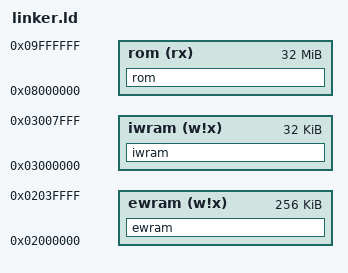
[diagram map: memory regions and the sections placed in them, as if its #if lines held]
ENTRY(__start)

gNumMusicPlayers = 0x20;
gMaxLines = 0;

MEMORY {
    ewram (w!x) : ORIGIN = 0x02000000, LENGTH = 256K
    iwram (w!x) : ORIGIN = 0x03000000, LENGTH = 32K
    rom (rx) : ORIGIN = 0x08000000, LENGTH = 32M
}

SECTIONS {
    ewram (NOLOAD) : ALIGN(4) {
        . = 0x00000010; gUnk_02000010 = .;
        . = 0x00000020; gUnk_02000020 = .;
        . = 0x00000030; gUnk_02000030 = .;
        . = 0x00000040; gUnk_02000040 = .;
        . = 0x00000050; gMessage = .;
        . = 0x00000070; gUpdateVisibleTiles = .;
        . = 0x00000080; gMenu = .;
        . = 0x00000080; gIntroState = .;
        . = 0x00000080; gChooseFileState = .;
        . = 0x00000090; gUnk_02000090 = .;
        . = 0x000000B0; gUnk_020000B0 = .;
        . = 0x000000C0; gUnk_020000C0 = .;
        . = 0x00000CC0; gBgAnimations = .;
        . = 0x00000D00; gTextGfxBuffer = .;
        . = 0x00001A00; gPaletteList = .;
        . = 0x00001A3C; gUnk_02001A3C = .;
        . = 0x00001A40; gBG3Buffer = .;
        . = 0x00002A40; gSave = .;
        . = 0x00002F00; gMapDataTopSpecial = .;
        . = 0x00006F00; gUnk_02006F00 = .;
        . = 0x0000AF00; gHUD = .;
        . = 0x0000AF34; gUnk_0200AF34 = .;
        . = 0x0000B240; gTilesForSpecialTiles = .;
        . = 0x0000B640; gUnk_0200B640 = .;
        . = 0x0000B644; gUsedPalettes = .;
        . = 0x0000B650; gMapTop = .;
        . = 0x00017654; gCurrentRoomProperties = .;
        . = 0x00017660; gSmallChests = .;
        . = 0x000176A0; gPaletteBuffer = .;
        . = 0x00017830; gUnk_02017830 = .;
        . = 0x00017AA0; gUnk_02017AA0 = .;
        . = 0x00017BA0; gUnk_02017BA0 = .;
        . = 0x00018EA0; gUnk_02018EA0 = .;
        . = 0x00018EB0; gUnk_02018EB0 = .;
        . = 0x00018EE0; gUnk_02018EE0 = .;
        . = 0x00019EE0; gMapDataBottomSpecial = .;
        . = 0x0001AEE0; gDungeonMap = .;
        . = 0x00021EE0; gSoundPlayingInfo = .;
        . = 0x00021F00; gUnk_02021F00 = .;
        . = 0x00021F20; gUnk_02021F20 = .;
        . = 0x00021F30; gBG1Buffer = .;
        . = 0x00022730; gVBlankDMA = .;
        . = 0x00022740; gFuseInfo = .;
        . = 0x00022750; gPlayerScriptExecutionContext = .;
        . = 0x00022780; gTextRender = .;
        . = 0x000227DC; gUnk_020227DC = .;
        . = 0x000227E8; gUnk_020227E8 = .;
        . = 0x000227F0; gUnk_020227F0 = .;
        . = 0x000227F8; gUnk_020227F8 = .;
        . = 0x00022800; gUnk_02022800 = .;
        . = 0x0002281D; gTextRenderUpdateDraw = .;
        . = 0x00022830; gUnk_02022830 = .;
        . = 0x00024030; gMessageChoices = .;
        . = 0x00024048; gUnk_02024048 = .;
        . = 0x00024050; gRoomMemory = .;
        . = 0x00024090; gPaletteBufferBackup = .;
        . = 0x00024490; gGFXSlots = .;
        . = 0x000246B0; gUnk_020246B0 = .;
        . = 0x00025EB0; gMapBottom = .;
        . = 0x00031EC0; gNPCData = .;
        . = 0x00032EC0; gUI = .;
        . = 0x00033280; gActiveScriptInfo = .;
        . = 0x00033290; gUnk_02033290 = .;
        . = 0x00033A90; gArea = .;
        . = 0x000342F8; gUnk_020342F8 = .;
        . = 0x00034330; gUnk_02034330 = .;
        . = 0x00034350; gRoomVars = .;
        . = 0x00034480; gUnk_02034480 = .;
        . = 0x00034490; gPauseMenuOptions = .;
        . = 0x00034492; gUnk_02034492 = .;
        . = 0x000344A0; gUnk_020344A0 = .;
        . = 0x000344B0; gBG2Buffer = .;
        . = 0x00034CB0; gBG0Buffer = .;
        . = 0x000354B0; gCurrentRoomMemory = .;
        . = 0x000354B4; gManagerCount = .;
        . = 0x000354C0; gUnk_020354C0 = .;
        . = 0x00035540; gzHeap = .;
        . = 0x00035542; gUnk_02035542 = .;
        . = 0x00036540; gUnk_02036540 = .;
        . = 0x00036570; gScriptExecutionContextArray = .;
        . = 0x000369F0; gEntityListsBackup = .;
        . = 0x00036A38; gCurrentWindow = .;
        . = 0x00036A40; gNewWindow = .;
#if defined(DEMO_USA) || defined(DEMO_JP)
        . = 0x00036A50; gUnk_02036A58 = .;
        . = 0x00036AD0; gUnk_02036AD8 = .;
        . = 0x00036BB0; gUnk_02036BB8 = .;
        . = 0x00036BB8; gMPlayTracks = .;
        . = 0x00038558; gEndOfEwram = .;
#else
        . = 0x00036A50; gEEPROMConfig = .;
        . = 0x00036A58; gUnk_02036A58 = .;
        . = 0x00036AD8; gUnk_02036AD8 = .;
        . = 0x00036BB8; gUnk_02036BB8 = .;
        . = 0x00036BC0; gMPlayTracks = .;
        . = 0x00038560; gEndOfEwram = .;
#endif
        . = 0x00040000;
    } >ewram

    iwram (NOLOAD) : ALIGN(4) {
        . = 0x00000000; gOAMControls = .;
        . = 0x00000420; gUnk_03000420 = .;
        . = 0x00000B80; gActiveItems = .;
        . = 0x00000BF0; gRoomControls = .;
        . = 0x00000C24; gUnk_03000C24 = .;
        . = 0x00000C30; gUnk_03000C30 = .;
        . = 0x00000E10; gCollidableList = .;
        . = 0x00000F50; gScreen = .;
        . = 0x00000FD0; gFadeControl = .;
        . = 0x00000FF0; gInput = .;
        . = 0x00001000; gMain = .;
        . = 0x00001010; gOamCmd = .;
        . = 0x00001020; gUnk_03001020 = .;
        . = 0x000010A0; gRoomTransition = .;
        . = 0x00001150; gRand = .;
        . = 0x00001160; gPlayerEntity = .;
        . = 0x000011E8; gAuxPlayerEntities = .;
        . = 0x000015A0; gEntities = .;
        . = 0x00003BE0; gCarriedEntity = .;
        . = 0x00003C70; gUnk_03003C70 = .;
        . = 0x00003D70; gEntityLists = .;
        . = 0x00003DB8; gCollidableCount = .;
        . = 0x00003DBC; gEntCount = .;
        . = 0x00003DC0; gPriorityHandler = .;
        . = 0x00003DD0; gUpdateContext = .;
        . = 0x00003DE0; gUnk_03003DE0 = .;
        . = 0x00003DE4; gUnk_03003DE4 = .;
        . = 0x00003DF0; gPossibleInteraction = .;
        . = 0x00003DF8; gInteractableObjects = .;
        . = 0x00003F80; gPlayerState = .;
        . = 0x00004030; gDiggingCaveEntranceTransition = .;
        . = 0x00004040; gPlayerClones = .;
        . = 0x0000404C; SoundMainRAM_Buffer = .;
        . = 0x0000404D; gUnk_0300404D = .;
        . = 0x000043D0; gSoundInfo = .;
        . = 0x00004D50; gMPlayJumpTable = .;
        . = 0x00004DE0; gCgbChans = .;
        . = 0x00004EE0; gMPlayInfos = .;
        . = 0x000055E0; gMPlayMemAccArea = .;
        . = 0x000055F0; gMPlayInfos2 = .;
/* ARM functions copied to IWRAM */
        . = 0x000056F0; ram_sub_080B197C = .;
        . = 0x00005740; ram_GetTileAtEntityPos = .;
        . = 0x0000574C; ram_sub_080B19D8 = .;
        . = 0x00005760; ram_sub_080B19EC = .;
        . = 0x00005770; ram_sub_080B19FC = .;
        . = 0x00005778; ram_sub_080B1A04 = .;
        . = 0x00005780; ram_GetTileTypeRelativeToEntity = .;
        . = 0x0000579C; ram_GetTileTypeAtEntity = .;
        . = 0x000057A8; ram_GetTileTypeAtWorldCoords = .;
        . = 0x000057BC; ram_GetTileTypeAtRoomCoords = .;
        . = 0x000057CC; ram_GetTileTypeAtRoomTile = .;
        . = 0x000057D4; ram_GetTileType = .;
        . = 0x00005800; ram_GetActTileRelativeToEntity = .;
        . = 0x0000581C; ram_GetActTileAtEntity = .;
        . = 0x00005828; ram_GetActTileAtWorldCoords = .;
        . = 0x0000583C; ram_GetActTileAtRoomCoords = .;
        . = 0x0000584C; ram_GetActTileAtRoomTile = .;
        . = 0x00005854; ram_GetActTileAtTilePos = .;
        . = 0x00005864; ram_GetCollisionDataRelativeTo = .;
        . = 0x00005880; ram_GetCollisionDataAtEntity = .;
        . = 0x0000588C; ram_GetCollisionDataAtWorldCoords = .;
        . = 0x000058A0; ram_GetCollisionDataAtRoomCoords = .;
        . = 0x000058B0; ram_GetCollisionDataAtRoomTile = .;
        . = 0x000058B8; ram_GetCollisionDataAtTilePos = .;
        . = 0x000058C8; ram_GetActTileForTileType = .;
        . = 0x000058DC; ram_sub_080B1B68 = .;
        . = 0x000058F8; ram_sub_080B1B84 = .;
        . = 0x00005918; ram_sub_080B1BA4 = .;
        . = 0x000059F0; ram_CollideAll = .;
        . = 0x00005CA4; ram_sub_080B1F30 = .;
        . = 0x00005CD0; ram_sub_080B1F5C = .;
        . = 0x00005CFC; ram_sub_080B1F88 = .;
        . = 0x00005D18; ram_sub_080B1FA4 = .;
        . = 0x00005D24; ram_sub_080B1FB0 = .;
        . = 0x00005D58; ram_sub_080B1FE4 = .;
        . = 0x00005D5C; ram_sub_080B1FE8 = .;
        . = 0x00005D90; ram_IntrMain = .;
        . = 0x00005E60; ram_CheckBits = .;
        . = 0x00005E98; ram_MakeFadeBuff256 = .;
        . = 0x00005F24; ram_ClearAndUpdateEntities = .;
        . = 0x00005F40; ram_UpdateEntities = .;
        . = 0x00005FBC; ram_sub_080B2248 = .;
        . = 0x00005FF0; ram_sub_080B227C = .;
        . = 0x000060F0; ram_CalcCollisionDirection = .;
        . = 0x00006164; ram_DrawEntities = .;
#if defined(EU) || defined(DEMO_JP)
        . = 0x000065AC; ram_DrawDirect = .;
        . = 0x000065C8; ram_sub_080ADA04 = .;
        . = 0x0000689C; ram_sub_080B2088 = .;
        . = 0x000068F0; ram_sub_080B20DC = .;
        . = 0x00006954; ram_sub_080B2140 = .;
        . = 0x000069AC; ram_gUnk_080B2A70 = .;
        . = 0x00006A94; ram_0x80b2b58 = .; /* TODO 0x80b2b58 in unusedLabel_080B2AA8*/
        . = 0x00006B14; ram_0x80b2bd8 = .; /* 0x80b2bd8 */
        . = 0x00006B24; ram_0x80b2be8 = .; /* 0x80b2be8 */
        . = 0x00006C14; usr_stack_top = .;
#else
        . = 0x00006580; ram_DrawDirect = .;
        . = 0x0000659C; ram_sub_080ADA04 = .;
        . = 0x000067E4; ram_gUnk_080B2A70 = .;
        . = 0x000068CC; ram_0x80b2b58 = .; /* TODO 0x80b2b58 in unusedLabel_080B2AA8*/
        . = 0x0000694C; ram_0x80b2bd8 = .; /* 0x80b2bd8 */
        . = 0x0000695C; ram_0x80b2be8 = .; /* 0x80b2be8 */
#endif
        . = 0x00007F00; usr_stack_begin = .;
        . = 0x00007FA0; irq_stack_begin = .;
        . = 0x00007FFA; soft_reset_flag = .;
        . = 0x00008000;
    } >iwram

    rom : ALIGN(2) {

        /* handwritten assembly */
        asm/src/crt0.o(.text);
#if defined(EU) || defined(DEMO_JP)
        asm/src/stack_check.o(.text);
#endif
        asm/src/veneer.o(.text);
        data/data_08000360.o(.rodata);
        asm/src/code_08000E44.o(.text);
        asm/lib/libgcc.o(.text);
        asm/src/code_08000F10.o(.text);
        data/data_08000F54.o(.rodata);
        asm/src/enemy.o(.text);
        src/droptables.o(.rodata);
        asm/src/code_08001A7C.o(.text);
        data/gfx/sprite_ptrs.o(.rodata);
        asm/src/code_08003FC4.o(.text);
        asm/src/code_080043E8.o(.text);
        src/data/data_080046A4.o(.rodata);
        data/gfx/link_animations.o(.rodata);
        src/data/mapActTileToSurfaceType.o(.rodata);
        asm/src/code_08007CAC.o(.text);
        data/data_08007DF4.o(.rodata);
        asm/src/player.o(.text);
        /* scripts */
        data/scripts.o(.text);
        asm/src/script.o(.text);
        asm/src/projectileUpdate.o(.text);

        /* C source compiled with interworking */
        src/interrupts.o(.text);
        src/playerItem.o(.text);
        src/object.o(.text);
        src/manager.o(.text);
        src/npcFunctions.o(.text);
        src/npc.o(.text);
        src/collision.o(.text);
        /* C source compiled without interworking */
        src/kinstone.o(.text);
        src/playerItem/playerItemGustBig.o(.text);
        src/playerItem/playerItemBow.o(.text);
        src/playerItem/playerItemSwordBeam.o(.text);
        src/beanstalkSubtask.o(.text);
        src/backgroundAnimations.o(.text);
        src/playerItem/playerItemBomb.o(.text);
        src/playerItem/playerItemBoomerang.o(.text);
        src/playerItem/playerItemDashSword.o(.text);
        src/playerItem/playerItemBottle.o(.text);
        src/playerItem/playerItemCellOverwriteSet.o(.text);
        src/ui.o(.text);
        src/color.o(.text);
        src/common.o(.text);
        /* enemies */
        src/enemy/octorok.o(.text);
        src/enemy/chuchu.o(.text);
        src/enemy/leever.o(.text);
        src/enemy/peahat.o(.text);
        src/enemy/rollobite.o(.text);
        src/enemy/darkNut.o(.text);
        src/enemy/hangingSeed.o(.text);
        src/enemy/beetle.o(.text);
        src/enemy/keese.o(.text);
        src/enemy/doorMimic.o(.text);
        src/enemy/rockChuchu.o(.text);
        src/enemy/spinyChuchu.o(.text);
        src/enemy/cuccoChickAggr.o(.text);
        src/enemy/moldorm.o(.text);
        src/enemy/enemyE.o(.text);
        src/enemy/moldworm.o(.text);
        src/enemy/sluggula.o(.text);
        src/enemy/pesto.o(.text);
        src/enemy/puffstool.o(.text);
        src/enemy/chuchuBoss.o(.text);
        src/enemy/likeLike.o(.text);
        src/enemy/spearMoblin.o(.text);
        src/enemy/businessScrub.o(.text);
        src/enemy/rupeeLike.o(.text);
        src/enemy/madderpillar.o(.text);
        src/enemy/waterDrop.o(.text);
        src/enemy/wallMaster.o(.text);
        src/enemy/bombPeahat.o(.text);
        src/enemy/spark.o(.text);
        src/enemy/chaser.o(.text);
        src/enemy/spikedBeetle.o(.text);
        src/enemy/sensorBladeTrap.o(.text);
        src/enemy/helmasaur.o(.text);
        src/enemy/fallingBoulder.o(.text);
        src/enemy/bobomb.o(.text);
        src/enemy/wallMaster2.o(.text);
        src/enemy/gleerok.o(.text);
        src/enemy/vaatiEyesMacro.o(.text);
        src/enemy/tektite.o(.text);
        src/enemy/wizzrobeWind.o(.text);
        src/enemy/wizzrobeFire.o(.text);
        src/enemy/wizzrobeIce.o(.text);
        src/enemy/armos.o(.text);
        src/enemy/eyegore.o(.text);
        src/enemy/rope.o(.text);
        src/enemy/smallPesto.o(.text);
        src/enemy/acroBandits.o(.text);
        src/enemy/bladeTrap.o(.text);
        src/enemy/keaton.o(.text);
        src/enemy/crow.o(.text);
        src/enemy/mulldozer.o(.text);
        src/enemy/bombarossa.o(.text);
        src/enemy/wisp.o(.text);
        src/enemy/spinyBeetle.o(.text);
        src/enemy/mazaalHead.o(.text);
        src/enemy/mazaalMacro.o(.text);
        src/enemy/mazaalHand.o(.text);
        src/enemy/octorokBoss.o(.text);
        src/enemy/flyingPot.o(.text);
        src/enemy/gibdo.o(.text);
        src/enemy/octorokGolden.o(.text);
        src/enemy/tektiteGolden.o(.text);
        src/enemy/ropeGolden.o(.text);
        src/enemy/cloudPiranha.o(.text);
        src/enemy/scissorsBeetle.o(.text);
        src/enemy/cuccoAggr.o(.text);
        src/enemy/stalfos.o(.text);
        src/enemy/flyingSkull.o(.text);
        src/enemy/mazaalBracelet.o(.text);
        src/enemy/takkuri.o(.text);
        src/enemy/bowMoblin.o(.text);
        src/enemy/lakitu.o(.text);
        src/enemy/lakituCloud.o(.text);
        src/enemy/torchTrap.o(.text);
        src/enemy/vaatiRebornEnemy.o(.text);
        src/enemy/vaatiProjectile.o(.text);
        src/enemy/ballChainSoldier.o(.text);
        src/enemy/enemy4D.o(.text);
        src/enemy/ghini.o(.text);
        src/enemy/vaatiTransfigured.o(.text);
        src/enemy/enemy50.o(.text);
        src/enemy/vaatiWrath.o(.text);
        src/enemy/vaatiArm.o(.text);
        src/enemy/dust.o(.text);
        src/enemy/vaatiBall.o(.text);
        src/enemy/slime.o(.text);
        src/enemy/sub_080451CC.o(.text);
        src/enemy/miniSlime.o(.text);
        src/enemy/fireballGuy.o(.text);
        src/enemy/miniFireballGuy.o(.text);
        src/enemy/vaatiTransfiguredEye.o(.text);
        src/enemy/businessScrubPrologue.o(.text);
        src/enemy/gyorgFemale.o(.text);
        src/enemy/gyorgMale.o(.text);
        src/enemy/curtain.o(.text);
        src/enemy/vaatiWrathEye.o(.text);
        src/enemy/gyorgChild.o(.text);
        src/enemy/gyorgFemaleEye.o(.text);
        src/enemy/gyorgMaleEye.o(.text);
        src/enemy/gyorgFemaleMouth.o(.text);
        src/enemy/enemy64.o(.text);
        src/enemy/treeItem.o(.text);
        src/enemy/enemy66.o(.text);
        /* END enemies */
        src/code_08049CD4.o(.text); /* enemyUtils.c */
        src/code_08049DF4.o(.text);
        src/enemyUtils.o(.text);
        src/enterPortalSubtask.o(.text);
        src/room.o(.text);
        src/roomInit.o(.text);
        src/fade.o(.text);
        src/fileselect.o(.text);
        src/game.o(.text);
        src/subtask/subtaskAuxCutscene.o(.text);
        src/gameOverTask.o(.text);
        src/gameUtils.o(.text);
        src/cutscene.o(.text);
        src/itemUtils.o(.text);
        src/subtask/subtaskWorldEvent.o(.text);
        src/playerItem/playerItemLantern.o(.text);
        src/worldEvent/worldEvent4.o(.text);
        src/worldEvent/worldEvent3.o(.text);
        src/worldEvent/worldEvent19.o(.text);
        src/worldEvent/worldEvent1.o(.text);
        src/worldEvent/worldEvent17.o(.text);
        src/worldEvent/worldEvent16.o(.text);
        src/worldEvent/worldEvent13.o(.text);
        src/worldEvent/worldEvent14.o(.text);
        src/worldEvent/worldEvent5.o(.text);
        src/worldEvent/worldEvent6.o(.text);
        src/worldEvent/worldEvent8.o(.text);
        src/worldEvent/worldEvent11.o(.text);
        src/worldEvent/worldEvent10.o(.text);
        src/worldEvent/worldEvent21.o(.text);
        src/worldEvent/worldEvent15.o(.text);
        src/worldEvent/worldEvent23.o(.text);
        src/worldEvent/worldEvent12.o(.text);
        src/worldEvent/worldEvent20.o(.text);
        src/worldEvent/worldEvent2.o(.text);
        src/worldEvent/worldEvent9.o(.text);
        src/worldEvent/worldEvent25.o(.text);
        src/worldEvent/worldEvent7.o(.text);
        src/worldEvent/worldEvent24.o(.text);
        src/worldEvent/worldEvent0.o(.text);
        src/worldEvent/worldEvent22.o(.text);
        src/main.o(.text);
        src/message.o(.text);
        src/manager/lightRayManager.o(.text);
        src/manager/verticalMinishPathBackgroundManager.o(.text);
        src/manager/minishPortalManager.o(.text);
        src/manager/diggingCaveEntranceManager.o(.text);
        src/manager/bridgeManager.o(.text);
        src/manager/specialWarpManager.o(.text);
        src/manager/minishVillageTileSetManager.o(.text);
        src/manager/horizontalMinishPathBackgroundManager.o(.text);
        src/manager/minishRaftersBackgroundManager.o(.text);
        src/manager/ezloHintManager.o(.text);
        src/manager/fightManager.o(.text);
        src/manager/rollingBarrelManager.o(.text);
        src/manager/tileChangeObserveManager.o(.text);
        src/manager/entitySpawnManager.o(.text);
        src/manager/miscManager.o(.text);
        src/manager/weatherChangeManager.o(.text);
        src/manager/flagAndOperatorManager.o(.text);
        src/manager/hyruleTownTileSetManager.o(.text);
        src/manager/houseSignManager.o(.text);
        src/manager/steamOverlayManager.o(.text);
        src/manager/templeOfDropletsManager.o(.text);
        src/manager/delayedEntityLoadManager.o(.text);
        src/manager/fallingItemManager.o(.text);
        src/manager/cloudOverlayManager.o(.text);
        src/manager/powBackgroundManager.o(.text);
        src/manager/holeManager.o(.text);
        src/manager/staticBackgroundManager.o(.text);
        src/manager/rainfallManager.o(.text);
        src/manager/animatedBackgroundManager.o(.text);
        src/manager/regionTriggerManager.o(.text);
        src/manager/railIntersectionManager.o(.text);
        src/manager/moveableObjectManager.o(.text);
        src/manager/minishSizedEntranceManager.o(.text);
        src/manager/lightManager.o(.text);
        src/manager/lightLevelSetManager.o(.text);
        src/manager/bombableWallManager.o(.text);
        src/manager/flameManager.o(.text);
        src/manager/pushableFurnitureManager.o(.text);
        src/manager/armosInteriorManager.o(.text);
        src/manager/enemyInteractionManager.o(.text);
        src/manager/manager29.o(.text);
        src/manager/destructibleTileObserveManager.o(.text);
        src/manager/angryStatueManager.o(.text);
        src/manager/cloudStaircaseTransitionManager.o(.text);
        src/manager/waterfallBottomManager.o(.text);
        src/manager/secretManager.o(.text);
        src/manager/vaati3BackgroundManager.o(.text);
        src/manager/tilePuzzleManager.o(.text);
        src/manager/goronMerchantShopManager.o(.text);
        src/manager/vaatiAppearingManager.o(.text);
        src/manager/hyruleTownBellManager.o(.text);
        src/manager/vaati3InsideArmManager.o(.text);
        src/manager/cameraTargetManager.o(.text);
        src/manager/repeatedSoundManager.o(.text);
        src/manager/vaati3StartManager.o(.text);
        src/manager/floatingPlatformManager.o(.text);
        src/manager/enterRoomTextboxManager.o(.text);
        src/entity.o(.text);
        src/code_0805EC04.o(.text); /* objaffine? */
        src/text.o(.text);
        src/debug.o(.text);
        src/playerItem/playerItemSpiralBeam.o(.text);
        /* npcs */
        src/npc/gentari.o(.text);
        src/npc/festari.o(.text);
        src/npc/forestMinish.o(.text);
        src/npc/postman.o(.text);
        src/npc/npc5.o(.text);
        src/npc/townsperson.o(.text);
        src/npc/kid.o(.text);
        src/npc/npc9.o(.text);
        src/npc/stamp.o(.text);
        src/npc/marcy.o(.text);
        src/npc/wheaton.o(.text);
        src/npc/pita.o(.text);
        src/npc/minishEzlo.o(.text);
        src/npc/mailbox.o(.text);
        src/npc/beedle.o(.text);
        src/npc/brocco.o(.text);
        src/npc/sittingPerson.o(.text);
        src/npc/pina.o(.text);
        src/npc/guard.o(.text);
        src/npc/guardWithSpear.o(.text);
        src/npc/castleMaid.o(.text);
        src/npc/din.o(.text);
        src/npc/nayru.o(.text);
        src/npc/farore.o(.text);
        src/npc/sturgeon.o(.text);
        src/npc/tingleSiblings.o(.text);
        src/npc/stockwell.o(.text);
        src/npc/talon.o(.text);
        src/npc/malon.o(.text);
        src/npc/epona.o(.text);
        src/npc/milkCart.o(.text);
        src/npc/ghostBrothers.o(.text);
        src/npc/smith.o(.text);
        src/npc/npc23.o(.text);
        src/npc/kingDaltus.o(.text);
        src/npc/ministerPotho.o(.text);
        src/npc/npc26.o(.text);
        src/npc/vaati.o(.text);
        src/npc/zelda.o(.text);
        src/npc/mutoh.o(.text);
        src/npc/carpenter.o(.text);
        src/npc/castorWildsStatue.o(.text);
        src/npc/cat.o(.text);
        src/npc/mountainMinish.o(.text);
        src/npc/zeldaFollower.o(.text);
        src/npc/melari.o(.text);
        src/npc/bladeBrothers.o(.text);
        src/npc/cow.o(.text);
        src/npc/goron.o(.text);
        src/npc/goronMerchant.o(.text);
        src/npc/gorman.o(.text);
        src/npc/dog.o(.text);
        src/npc/syrup.o(.text);
        src/npc/rem.o(.text);
        src/npc/townMinish.o(.text);
        src/npc/librari.o(.text);
        src/npc/percy.o(.text);
        src/npc/vaatiReborn.o(.text);
        src/npc/moblinLady.o(.text);
        src/npc/librarians.o(.text);
        src/npc/farmers.o(.text);
        src/npc/carlov.o(.text);
        src/npc/dampe.o(.text);
        src/npc/drLeft.o(.text);
        src/npc/kingGustaf.o(.text);
        src/npc/gina.o(.text);
        src/npc/simon.o(.text);
        src/npc/anju.o(.text);
        src/npc/mama.o(.text);
        src/npc/emma.o(.text);
        src/npc/teachers.o(.text);
        src/npc/windTribespeople.o(.text);
        src/npc/gregal.o(.text);
        src/npc/mayorHagen.o(.text);
        src/npc/bigGoron.o(.text);
        src/npc/ezlo.o(.text);
        src/npc/npc4E.o(.text);
        src/npc/npc4F.o(.text);
        src/npc/clothesRack.o(.text);
        src/npc/picolyteBottle.o(.text);
        src/npc/smallTownMinish.o(.text);
        src/npc/hurdyGurdyMan.o(.text);
        src/npc/cucco.o(.text);
        src/npc/cuccoChick.o(.text);
        src/npc/fusionMenuNPC.o(.text);
        src/npc/phonograph.o(.text);
        src/npc/npc58.o(.text);
        /* END npcs */
        src/npcUtils.o(.text);
        src/physics.o(.text);
        src/playerItem/playerItemPacciCaneProjectile.o(.text);
        src/playerItem/playerItemPacciCane.o(.text);
        src/player.o(.text);
        src/item.o(.text);
        src/item/itemDebug.o(.text);
        src/item/itemSword.o(.text);
        src/item/itemLantern.o(.text);
        src/item/itemBoomerang.o(.text);
        src/item/itemBow.o(.text);
        src/item/itemBomb.o(.text);
        src/item/itemTryPickupObject.o(.text);
        src/item/itemRocsCape.o(.text);
        src/item/itemPegasusBoots.o(.text);
        src/item/itemOcarina.o(.text);
        src/item/itemPacciCane.o(.text);
        src/item/itemShield.o(.text);
        src/item/itemGustJar.o(.text);
        src/item/itemMoleMitts.o(.text);
        src/item/itemJarEmpty.o(.text);
        src/playerUtils.o(.text);
        src/flags.o(.text);
        src/save.o(.text);
        src/screenTileMap.o(.text);
        src/script.o(.text);
        src/scroll.o(.text);
        /* objects */
        src/object/itemOnGround.o(.text);
        src/object/deathFx.o(.text);
        src/object/itemForSale.o(.text);
        src/object/button.o(.text);
        src/object/minishEmoticon.o(.text);
        src/object/pot.o(.text);
        src/object/ezloCap.o(.text);
        src/object/blockPushed.o(.text);
        src/object/lockedDoor.o(.text);
        src/object/cameraTarget.o(.text);
        src/object/objectA.o(.text);
        src/object/linkHoldingItem.o(.text);
        src/object/chestSpawner.o(.text);
        src/object/unusedSkull.o(.text);
        src/object/crackingGround.o(.text);
        src/object/specialFx.o(.text);
        src/object/playerClone.o(.text);
        src/object/bush.o(.text);
        src/object/lightDoor.o(.text);
        src/object/railtrack.o(.text);
        src/object/lilypadLarge.o(.text);
        src/object/chuchuBossParticle.o(.text);
        src/object/floatingPlatform.o(.text);
        src/object/gustJarParticle.o(.text);
        src/object/evilSpirit.o(.text);
        src/object/houseDoorExterior.o(.text);
        src/object/rupee.o(.text);
        src/object/greatFairy.o(.text);
        src/object/houseSign.o(.text);
        src/object/object1D.o(.text);
        src/object/moleMittsParticle.o(.text);
        src/object/object1F.o(.text);
        src/object/smokeParticle.o(.text);
        src/object/dirtParticle.o(.text);
        src/object/figurineDevice.o(.text);
        src/object/eyeSwitch.o(.text);
        src/object/pressurePlate.o(.text);
        src/object/bigBarrel.o(.text);
        src/object/barrelInside.o(.text);
        src/object/pushableStatue.o(.text);
        src/object/parallaxRoomView.o(.text);
        src/object/ambientClouds.o(.text);
        src/object/flame.o(.text);
        src/object/lilypadLargeFalling.o(.text);
        src/object/beanstalk.o(.text);
        src/object/smoke.o(.text);
        src/object/pushableRock.o(.text);
        src/object/hittableLever.o(.text);
        src/object/object30.o(.text);
        src/object/frozenFlower.o(.text);
        src/object/pullableMushroom.o(.text);
        src/object/bollard.o(.text);
        src/object/warpPoint.o(.text);
        src/object/carlovObject.o(.text);
        src/object/barrelSpiderweb.o(.text);
        src/object/object37.o(.text);
        src/object/jarPortal.o(.text);
        src/object/bossDoor.o(.text);
        src/object/whiteTriangleEffect.o(.text);
        src/object/macroMushroomStalk.o(.text);
        src/object/macroPlayer.o(.text);
        src/object/minishPortalCloseup.o(.text);
        src/object/minishVillageObject.o(.text);
        src/object/giantLeaf.o(.text);
        src/object/fairy.o(.text);
        src/object/ladderUp.o(.text);
        src/object/linkFire.o(.text);
        src/object/swordParticle.o(.text);
        src/object/rotatingTrapdoor.o(.text);
        src/object/lampParticle.o(.text);
        src/object/giantBookLadder.o(.text);
        src/object/heartContainer.o(.text);
        src/object/fileScreenObjects.o(.text);
        src/object/chuchuBossStartParticle.o(.text);
        src/object/backgroundCloud.o(.text);
        src/object/chuchuBossCutscene.o(.text);
        src/object/pushableFurniture.o(.text);
        src/object/furniture.o(.text);
        src/object/minishSizedEntrance.o(.text);
        src/object/archway.o(.text);
        src/object/giantRock.o(.text);
        src/object/giantRock2.o(.text);
        src/object/specialChest.o(.text);
        src/object/object53.o(.text);
        src/object/pullableLever.o(.text);
        src/object/minecart.o(.text);
        src/object/thoughtBubble.o(.text);
        src/object/hiddenLadderDown.o(.text);
        src/object/gentariCurtain.o(.text);
        src/object/lavaPlatform.o(.text);
        src/object/paper.o(.text);
        src/object/bedCover.o(.text);
        src/object/mask.o(.text);
        src/object/houseDoorInterior.o(.text);
        src/object/whirlwind.o(.text);
        src/object/objectBlockingStairs.o(.text);
        src/object/swordsmanNewsletter.o(.text);
        src/object/ezloCapFlying.o(.text);
        src/object/giantTwig.o(.text);
        src/object/object63.o(.text);
        src/object/thunderbolt.o(.text);
        src/object/ladderHoleInBookshelf.o(.text);
        src/object/waterDropObject.o(.text);
        src/object/gleerokParticle.o(.text);
        src/object/linkEmptyingBottle.o(.text);
        src/object/cutsceneOrchestrator.o(.text);
        src/object/cutsceneMiscObject.o(.text);
        src/object/crenelBeanSprout.o(.text);
        src/object/minecartDoor.o(.text);
        src/object/objectOnPillar.o(.text);
        src/object/mineralWaterSource.o(.text);
        src/object/minishSizedArchway.o(.text);
        src/object/object70.o(.text);
        src/object/pushableGrave.o(.text);
        src/object/stoneTablet.o(.text);
        src/object/lilypadSmall.o(.text);
        src/object/minishPortalStone.o(.text);
        src/object/bell.o(.text);
        src/object/macroDecorations.o(.text);
        src/object/shrinkingHieroglyphs.o(.text);
        src/object/steam.o(.text);
        src/object/pushableLever.o(.text);
        src/object/macroShoe.o(.text);
        src/object/objectOnSpinyBeetle.o(.text);
        src/object/mazaalObject.o(.text);
        src/object/picoBloom.o(.text);
        src/object/board.o(.text);
        src/object/bench.o(.text);
        src/object/bigVortex.o(.text);
        src/object/bigPushableLever.o(.text);
        src/object/smallIceBlock.o(.text);
        src/object/bigIceBlock.o(.text);
        src/object/trapdoor.o(.text);
        src/object/octorokBossObject.o(.text);
        src/object/macroBook.o(.text);
        src/object/mazaalBossObject.o(.text);
        src/object/cabinFurniture.o(.text);
        src/object/doubleBookshelf.o(.text);
        src/object/book.o(.text);
        src/object/fireplace.o(.text);
        src/object/lightRay.o(.text);
        src/object/frozenWaterElement.o(.text);
        src/object/waterElement.o(.text);
        src/object/frozenOctorok.o(.text);
        src/object/bakerOven.o(.text);
        src/object/lamp.o(.text);
        src/object/windTribeFlag.o(.text);
        src/object/bird.o(.text);
        src/object/graveyardKey.o(.text);
        src/object/keyStealingTakkuri.o(.text);
        src/object/guruguruBar.o(.text);
        src/object/hitSwitch.o(.text);
        src/object/macroAcorn.o(.text);
        src/object/vaati2Particle.o(.text);
        src/object/treeHidingPortal.o(.text);
        src/object/lightableSwitch.o(.text);
        src/object/treeThorns.o(.text);
        src/object/fan.o(.text);
        src/object/angryStatue.o(.text);
        src/object/palaceArchway.o(.text);
        src/object/objectA2.o(.text);
        src/object/cloud.o(.text);
        src/object/minishLight.o(.text);
        src/object/fireballChain.o(.text);
        src/object/sanctuaryStoneTablet.o(.text);
        src/object/objectA7.o(.text);
        src/object/objectA8.o(.text);
        src/object/mulldozerSpawnPoint.o(.text);
        src/object/waterfallOpening.o(.text);
        src/object/vaati1Portal.o(.text);
        src/object/fourElements.o(.text);
        src/object/elementsBackground.o(.text);
        src/object/floatingBlock.o(.text);
        src/object/vaati3Arm.o(.text);
        src/object/metalDoor.o(.text);
        src/object/jailBars.o(.text);
        src/object/fanWind.o(.text);
        src/object/kinstoneSpark.o(.text);
        src/object/japaneseSubtitle.o(.text);
        src/object/vaati3PlayerObject.o(.text);
        src/object/vaati3Death.o(.text);
        src/object/well.o(.text);
        src/object/windTribeTeleporter.o(.text);
        src/object/cuccoMinigame.o(.text);
        src/object/gyorgBossObject.o(.text);
        src/object/windcrest.o(.text);
        src/object/litArea.o(.text);
        src/object/titleScreenObject.o(.text);
        src/object/pinwheel.o(.text);
        src/object/objectBF.o(.text);
        src/object/enemyItem.o(.text);
        src/object/linkAnimation.o(.text);
        /* END objects */
        src/objectUtils.o(.text);
        src/playerItem/playerItemShield.o(.text);
        src/playerItem/playerItemFireRodProjectile.o(.text);
#ifdef DEMO_USA
        src/demo.o(.text);
#endif
        src/sound.o(.text);
        src/staffroll.o(.text);
        src/menu/kinstoneMenu.o(.text);
        src/menu/figurineMenu.o(.text);
        src/menu/pauseMenu.o(.text);
        src/subtask/subtaskMapHint.o(.text);
        src/menu/pauseMenuScreen6.o(.text);
        src/subtask/subtaskLocalMapHint.o(.text);
        src/subtask/subtaskFastTravel.o(.text);
        src/subtask.o(.text);
        src/playerItem/playerItemSword.o(.text);
        src/playerItemUtils.o(.text);
        src/projectileUtils.o(.text);
        src/projectile/darkNutSwordSlash.o(.text);
        src/projectile/rockProjectile.o(.text);
        src/projectile/boneProjectile.o(.text);
        src/projectile/moblinSpear.o(.text);
        src/projectile/dekuSeedProjectile.o(.text);
        src/projectile/projectile5.o(.text);
        src/projectile/dirtBallProjectile.o(.text);
        src/projectile/windProjectile.o(.text);
        src/projectile/fireProjectile.o(.text);
        src/projectile/iceProjectile.o(.text);
        src/projectile/gleerokProjectile.o(.text);
        src/projectile/keatonDagger.o(.text);
        src/projectile/guardLineOfSight.o(.text);
        src/projectile/arrowProjectile.o(.text);
        src/projectile/mazaalEnergyBeam.o(.text);
        src/projectile/octorokBossProjectile.o(.text);
        src/projectile/stalfosProjectile.o(.text);
        src/projectile/lakituCloudProjectile.o(.text);
        src/projectile/lakituLightning.o(.text);
        src/projectile/mandiblesProjectile.o(.text);
        src/projectile/removableDust.o(.text);
        src/projectile/spiderWeb.o(.text);
        src/projectile/torchTrapProjectile.o(.text);
        src/projectile/guruguruBarProjectile.o(.text);
        src/projectile/v1DarkMagicProjectile.o(.text);
        src/projectile/ballAndChain.o(.text);
        src/projectile/v1FireProjectile.o(.text);
        src/projectile/cannonballProjectile.o(.text);
        src/projectile/v1EyeLaser.o(.text);
        src/projectile/winder.o(.text);
        src/projectile/spikedRollers.o(.text);
        src/projectile/v2Projectile.o(.text);
        src/projectile/v3HandProjectile.o(.text);
        src/projectile/v3ElectricProjectile.o(.text);
        src/projectile/gyorgTail.o(.text);
        src/projectile/gyorgMaleEnergyProjectile.o(.text);
        src/projectile/v3TennisBallProjectile.o(.text);
        src/playerItem/playerItemGust.o(.text);
        src/playerItem/playerItemHeldObject.o(.text);
        src/title.o(.text);
        src/affine.o(.text);
        src/playerItem/playerItemGustJar.o(.text);
        src/vram.o(.text);
        src/movement.o(.text);
        /* library functions */
        asm/lib/m4a_asm.o(.text);
        src/gba/m4a.o(.text);
        asm/lib/libagbsyscall.o(.text);
        src/eeprom.o(.text);
        *libc.a:memcpy.o(.text);
        /* handwritten assembly in arm mode */
        asm/src/intr.o(.text);

        /* data */
        data/const/interrupts.o(.rodata);
        src/interrupts.o(.rodata);
        src/playerItem.o(.rodata);
        src/object.o(.rodata);
        src/manager.o(.rodata);
        src/npcFunctions.o(.rodata);
        src/npc.o(.rodata);
        src/collision.o(.rodata);
        src/kinstone.o(.rodata);
        src/playerItem/playerItemGustBig.o(.rodata);
        src/playerItem/playerItemBow.o(.rodata);
        src/playerItem/playerItemSwordBeam.o(.rodata);
        data/const/beanstalkSubtask.o(.rodata);
        src/beanstalkSubtask.o(.rodata);
        src/backgroundAnimations.o(.rodata);
        src/playerItem/playerItemBomb.o(.rodata);
        src/playerItem/playerItemBoomerang.o(.rodata);
        src/playerItem/playerItemDashSword.o(.rodata);
        src/playerItem/playerItemBottle.o(.rodata);
        src/playerItem/playerItemCellOverwriteSet.o(.rodata);
        data/const/collisionMatrix.o(.rodata);
        data/const/ui.o(.rodata);
        src/sineTable.o(.rodata);
        src/common.o(.rodata);
        src/enemy/octorok.o(.rodata);
        data/animations/enemy/octorok.o(.rodata);
        src/enemy/chuchu.o(.rodata);
        data/animations/enemy/chuchu.o(.rodata);
        src/enemy/leever.o(.rodata);
        data/animations/enemy/leever.o(.rodata);
        src/enemy/peahat.o(.rodata);
        data/animations/enemy/peahat.o(.rodata);
        src/enemy/rollobite.o(.rodata);
        data/animations/enemy/rollobite.o(.rodata);
        src/enemy/darkNut.o(.rodata);
        data/animations/enemy/darkNut.o(.rodata);
        src/enemy/hangingSeed.o(.rodata);
        src/enemy/beetle.o(.rodata);
        data/animations/enemy/beetle.o(.rodata);
        src/enemy/keese.o(.rodata);
        data/animations/enemy/keese.o(.rodata);
        src/enemy/doorMimic.o(.rodata);
        data/animations/enemy/doorMimic.o(.rodata);
        src/enemy/rockChuchu.o(.rodata);
        data/animations/enemy/rockChuchu.o(.rodata);
        src/enemy/spinyChuchu.o(.rodata);
        data/animations/enemy/spinyChuchu.o(.rodata);
        src/enemy/cuccoChickAggr.o(.rodata);
        src/enemy/moldorm.o(.rodata);
        src/enemy/enemyE.o(.rodata);
        data/animations/enemy/enemyE.o(.rodata);
        src/enemy/moldworm.o(.rodata);
        data/animations/enemy/moldworm.o(.rodata);
        src/enemy/sluggula.o(.rodata);
        data/animations/enemy/sluggula.o(.rodata);
        src/enemy/pesto.o(.rodata);
        data/animations/enemy/pesto.o(.rodata);
        src/enemy/puffstool.o(.rodata);
        data/animations/enemy/puffstool.o(.rodata);
        src/enemy/chuchuBoss.o(.rodata);
        data/animations/enemy/chuchuBoss.o(.rodata);
        src/enemy/likeLike.o(.rodata);
        data/animations/enemy/likeLike.o(.rodata);
        src/enemy/spearMoblin.o(.rodata);
        data/animations/enemy/spearMoblin.o(.rodata);
        src/enemy/businessScrub.o(.rodata);
        data/animations/enemy/businessScrub.o(.rodata);
        src/enemy/rupeeLike.o(.rodata);
        data/animations/enemy/rupeeLike.o(.rodata);
        src/enemy/madderpillar.o(.rodata);
        data/animations/enemy/madderpillar.o(.rodata);
        src/enemy/waterDrop.o(.rodata);
        data/animations/enemy/waterDrop.o(.rodata);
        src/enemy/wallMaster.o(.rodata);
        data/animations/enemy/wallMaster.o(.rodata);
        src/enemy/bombPeahat.o(.rodata);
        data/animations/enemy/bombPeahat.o(.rodata);
        src/enemy/spark.o(.rodata);
        data/animations/enemy/spark.o(.rodata);
        src/enemy/chaser.o(.rodata);
        data/animations/enemy/chaser.o(.rodata);
        src/enemy/spikedBeetle.o(.rodata);
        data/animations/enemy/spikedBeetle.o(.rodata);
        src/enemy/sensorBladeTrap.o(.rodata);
        src/enemy/helmasaur.o(.rodata);
        data/animations/enemy/helmasaur.o(.rodata);
        src/enemy/fallingBoulder.o(.rodata);
        data/animations/enemy/fallingBoulder.o(.rodata);
        src/enemy/bobomb.o(.rodata);
        data/animations/enemy/bobomb.o(.rodata);
        src/enemy/wallMaster2.o(.rodata);
        src/enemy/gleerok.o(.rodata);
        data/const/enemy/gleerok.o(.rodata);
        data/animations/enemy/gleerok.o(.rodata);
        src/enemy/vaatiEyesMacro.o(.rodata);
        data/animations/enemy/vaatiEyesMacro.o(.rodata);
        src/enemy/tektite.o(.rodata);
        data/animations/enemy/tektite.o(.rodata);
        src/enemy/wizzrobeWind.o(.rodata);
        data/animations/enemy/wizzrobeWind.o(.rodata);
        src/enemy/wizzrobeFire.o(.rodata);
        data/animations/enemy/wizzrobeFire.o(.rodata);
        src/enemy/wizzrobeIce.o(.rodata);
        data/animations/enemy/wizzrobeIce.o(.rodata);
        src/enemy/armos.o(.rodata);
        data/animations/enemy/armos.o(.rodata);
        src/enemy/eyegore.o(.rodata);
        data/animations/enemy/eyegore.o(.rodata);
        src/enemy/rope.o(.rodata);
        data/animations/enemy/rope.o(.rodata);
        src/enemy/smallPesto.o(.rodata);
        src/enemy/acroBandits.o(.rodata);
        data/animations/enemy/acroBandits.o(.rodata);
        src/enemy/keaton.o(.rodata);
        data/animations/enemy/keaton.o(.rodata);
        src/enemy/crow.o(.rodata);
        data/animations/enemy/crow.o(.rodata);
        src/enemy/mulldozer.o(.rodata);
        data/animations/enemy/mulldozer.o(.rodata);
        src/enemy/bombarossa.o(.rodata);
        data/animations/enemy/bombarossa.o(.rodata);
        src/enemy/wisp.o(.rodata);
        data/animations/enemy/wisp.o(.rodata);
        src/enemy/spinyBeetle.o(.rodata);
        data/animations/enemy/spinyBeetle.o(.rodata);
        src/enemy/mazaalHead.o(.rodata);
        data/animations/enemy/mazaalHead.o(.rodata);
        src/enemy/mazaalMacro.o(.rodata);
        data/animations/enemy/mazaalMacro.o(.rodata);
        src/enemy/mazaalHand.o(.rodata);
        data/animations/enemy/mazaalHand.o(.rodata);
        src/enemy/octorokBoss.o(.rodata);
        data/animations/enemy/octorokBoss.o(.rodata);
        src/enemy/flyingPot.o(.rodata);
        src/enemy/gibdo.o(.rodata);
        data/animations/enemy/gibdo.o(.rodata);
        src/enemy/octorokGolden.o(.rodata);
        src/enemy/tektiteGolden.o(.rodata);
        src/enemy/ropeGolden.o(.rodata);
        src/enemy/cloudPiranha.o(.rodata);
        data/animations/enemy/cloudPiranha.o(.rodata);
        src/enemy/scissorsBeetle.o(.rodata);
        data/animations/enemy/scissorsBeetle.o(.rodata);
        src/enemy/cuccoAggr.o(.rodata);
        data/animations/enemy/cuccoAggr.o(.rodata);
        src/enemy/stalfos.o(.rodata);
        data/animations/enemy/stalfos.o(.rodata);
        src/enemy/flyingSkull.o(.rodata);
        data/animations/enemy/flyingSkull.o(.rodata);
        src/enemy/mazaalBracelet.o(.rodata);
        data/animations/enemy/mazaalBracelet.o(.rodata);
        src/enemy/takkuri.o(.rodata);
        src/enemy/bowMoblin.o(.rodata);
        data/animations/enemy/bowMoblin.o(.rodata);
        src/enemy/lakitu.o(.rodata);
        data/animations/enemy/lakitu.o(.rodata);
        src/enemy/lakituCloud.o(.rodata);
        src/enemy/torchTrap.o(.rodata);
        src/enemy/vaatiRebornEnemy.o(.rodata);
        data/animations/enemy/vaatiRebornEnemy.o(.rodata);
        src/enemy/vaatiProjectile.o(.rodata);
        data/animations/enemy/vaatiProjectile.o(.rodata);
        src/enemy/ballChainSoldier.o(.rodata);
        data/animations/enemy/ballChainSoldier.o(.rodata);
        src/enemy/enemy4D.o(.rodata);
        src/enemy/ghini.o(.rodata);
        data/animations/enemy/ghini.o(.rodata);
        src/enemy/vaatiTransfigured.o(.rodata);
        data/animations/enemy/vaatiTransfigured.o(.rodata);
        src/enemy/enemy50.o(.rodata);
        src/enemy/vaatiWrath.o(.rodata);
        data/animations/enemy/vaatiWrath.o(.rodata);
        src/enemy/vaatiArm.o(.rodata);
        data/animations/enemy/vaatiArm.o(.rodata);
        src/enemy/dust.o(.rodata);
        data/const/enemy/dust.o(.rodata);
        src/enemy/vaatiBall.o(.rodata);
        data/animations/enemy/vaatiBall.o(.rodata);
        src/enemy/slime.o(.rodata);
        data/animations/enemy/slime.o(.rodata);
        src/enemy/miniSlime.o(.rodata);
        src/enemy/fireballGuy.o(.rodata);
        data/animations/enemy/fireballGuy.o(.rodata);
        src/enemy/miniFireballGuy.o(.rodata);
        src/enemy/vaatiTransfiguredEye.o(.rodata);
        data/animations/enemy/vaatiTransfiguredEye.o(.rodata);
        src/enemy/businessScrubPrologue.o(.rodata);
        src/enemy/gyorgFemale.o(.rodata);
        src/enemy/gyorgMale.o(.rodata);
        data/animations/enemy/gyorgMale.o(.rodata);
        src/enemy/curtain.o(.rodata);
        data/animations/enemy/curtain.o(.rodata);
        src/enemy/vaatiWrathEye.o(.rodata);
        data/animations/enemy/vaatiWrathEye.o(.rodata);
        src/enemy/gyorgChild.o(.rodata);
        data/animations/enemy/gyorgChild.o(.rodata);
        src/enemy/gyorgFemaleEye.o(.rodata);
        data/animations/enemy/gyorgFemaleEye.o(.rodata);
        src/enemy/gyorgMaleEye.o(.rodata);
        data/animations/enemy/gyorgMaleEye.o(.rodata);
        src/enemy/gyorgFemaleMouth.o(.rodata);
        data/animations/enemy/gyorgFemaleMouth.o(.rodata);
        src/enemy/enemy64.o(.rodata);
        src/enemy/treeItem.o(.rodata);
        src/enemy/enemy66.o(.rodata);
        src/enemy.o(.rodata);
        src/enemyUtils.o(.rodata);
        src/enterPortalSubtask.o(.rodata);
        data/map/entity_headers.o(.rodata);
        src/fade.o(.rodata);
        src/fileselect.o(.rodata);
        src/game.o(.rodata);
        src/subtask/subtaskAuxCutscene.o(.rodata);
        src/gameOverTask.o(.rodata);
        src/gameUtils.o(.rodata);
        src/cutscene.o(.rodata);
        src/data/hitbox.o(.rodata);
        src/itemUtils.o(.rodata);
        src/subtask/subtaskWorldEvent.o(.rodata);
        src/itemMetaData.o(.rodata);
        data/animations/spriteAnimations322.o(.rodata);
        src/gameData.o(.rodata);
        data/const/game_2.o(.rodata);
        src/playerItem/playerItemLantern.o(.rodata);
        src/worldEvent/worldEvent4.o(.rodata);
        src/worldEvent/worldEvent3.o(.rodata);
        src/worldEvent/worldEvent19.o(.rodata);
        src/worldEvent/worldEvent1.o(.rodata);
        src/worldEvent/worldEvent17.o(.rodata);
        src/worldEvent/worldEvent16.o(.rodata);
        src/worldEvent/worldEvent13.o(.rodata);
        src/worldEvent/worldEvent14.o(.rodata);
        src/worldEvent/worldEvent5.o(.rodata);
        src/worldEvent/worldEvent6.o(.rodata);
        src/worldEvent/worldEvent8.o(.rodata);
        src/worldEvent/worldEvent11.o(.rodata);
        src/worldEvent/worldEvent10.o(.rodata);
        src/worldEvent/worldEvent21.o(.rodata);
        src/worldEvent/worldEvent15.o(.rodata);
        src/worldEvent/worldEvent23.o(.rodata);
        src/worldEvent/worldEvent12.o(.rodata);
        src/worldEvent/worldEvent20.o(.rodata);
        src/worldEvent/worldEvent2.o(.rodata);
        src/worldEvent/worldEvent9.o(.rodata);
        src/worldEvent/worldEvent25.o(.rodata);
        src/worldEvent/worldEvent7.o(.rodata);
        src/worldEvent/worldEvent24.o(.rodata);
        src/worldEvent/worldEvent0.o(.rodata);
        src/worldEvent/worldEvent22.o(.rodata);
        data/gfx/palette_groups.o(.rodata);
        data/gfx/gfx_groups.o(.rodata);
        src/main.o(.rodata);
        data/map/tileset_headers.o(.rodata);
        data/map/tile_headers.o(.rodata);
        data/map/map_headers.o(.rodata);
        src/message.o(.rodata);
        . = ALIGN(4);
        src/manager/lightRayManager.o(.rodata);
        src/manager/minishPortalManager.o(.rodata);
        src/manager/diggingCaveEntranceManager.o(.rodata);
        src/manager/bridgeManager.o(.rodata);
        src/manager/minishVillageTileSetManager.o(.rodata);
        . = ALIGN(4);
        src/manager/minishRaftersBackgroundManager.o(.rodata);
        src/manager/ezloHintManager.o(.rodata);
        src/manager/fightManager.o(.rodata);
        src/manager/rollingBarrelManager.o(.rodata);
        src/manager/tileChangeObserveManager.o(.rodata);
        src/manager/miscManager.o(.rodata);
        src/manager/weatherChangeManager.o(.rodata);
        src/manager/hyruleTownTileSetManager.o(.rodata);
        src/manager/houseSignManager.o(.rodata);
        src/manager/steamOverlayManager.o(.rodata);
        src/manager/templeOfDropletsManager.o(.rodata);
        src/manager/fallingItemManager.o(.rodata);
        src/manager/cloudOverlayManager.o(.rodata);
        data/const/manager/holeManager.o(.rodata);
        src/manager/staticBackgroundManager.o(.rodata);
        src/manager/rainfallManager.o(.rodata);
        src/manager/animatedBackgroundManager.o(.rodata);
        src/manager/regionTriggerManager.o(.rodata);
        src/manager/railIntersectionManager.o(.rodata);
        src/manager/lightManager.o(.rodata);
        src/manager/lightLevelSetManager.o(.rodata);
        src/manager/bombableWallManager.o(.rodata);
        src/manager/pushableFurnitureManager.o(.rodata);
        src/manager/armosInteriorManager.o(.rodata);
        src/manager/enemyInteractionManager.o(.rodata);
        src/manager/angryStatueManager.o(.rodata);
        src/manager/secretManager.o(.rodata);
        src/manager/goronMerchantShopManager.o(.rodata);
        src/manager/vaatiAppearingManager.o(.rodata);
        src/manager/vaati3InsideArmManager.o(.rodata);
        src/manager/cameraTargetManager.o(.rodata);
        src/manager/repeatedSoundManager.o(.rodata);
        src/manager/vaati3StartManager.o(.rodata);
        src/manager/floatingPlatformManager.o(.rodata);
        src/manager/enterRoomTextboxManager.o(.rodata);
        data/const/manager/enterRoomTextboxManager.o(.rodata);
        src/data/caveBorderMapData.o(.rodata);
        src/entity.o(.rodata);
        src/code_0805EC04.o(.rodata);
        data/const/text.o(.rodata);
        src/debug.o(.rodata);
        src/playerItem/playerItemSpiralBeam.o(.rodata);
        data/animations/npc/gentari.o(.rodata);
        src/npc/festari.o(.rodata);
        data/animations/npc/festari.o(.rodata);
        src/npc/forestMinish.o(.rodata);
        data/animations/npc/forestMinish.o(.rodata);
        src/npc/postman.o(.rodata);
        data/animations/npc/postman.o(.rodata);
        src/npc/npc5.o(.rodata);
        data/animations/npc/npc5.o(.rodata);
        data/const/npc/townsperson.o(.rodata);
        data/animations/npc/townsperson.o(.rodata);
        src/npc/kid.o(.rodata);
        data/animations/npc/kid.o(.rodata);
        src/npc/npc9.o(.rodata);
        data/animations/npc/npc9.o(.rodata);
        src/npc/stamp.o(.rodata);
        data/animations/npc/stamp.o(.rodata);
        src/npc/marcy.o(.rodata);
        data/animations/npc/marcy.o(.rodata);
        src/npc/wheaton.o(.rodata);
        data/animations/npc/wheaton.o(.rodata);
        src/npc/pita.o(.rodata);
        data/animations/npc/pita.o(.rodata);
        src/npc/minishEzlo.o(.rodata);
        data/animations/npc/minishEzlo.o(.rodata);
        src/npc/mailbox.o(.rodata);
        data/animations/npc/mailbox.o(.rodata);
        src/npc/beedle.o(.rodata);
        data/animations/npc/beedle.o(.rodata);
        src/npc/brocco.o(.rodata);
        data/animations/npc/brocco.o(.rodata);
        src/npc/sittingPerson.o(.rodata);
        data/animations/npc/sittingPerson.o(.rodata);
        src/npc/pina.o(.rodata);
        data/animations/npc/pina.o(.rodata);
        src/npc/guard.o(.rodata);
        data/const/npc/guard.o(.rodata);
        src/npc/guardWithSpear.o(.rodata);
        data/animations/npc/guardWithSpear.o(.rodata);
        src/npc/castleMaid.o(.rodata);
        data/animations/npc/maid.o(.rodata);
        data/animations/npc/din.o(.rodata);
        data/animations/npc/nayru.o(.rodata);
        data/animations/npc/farore.o(.rodata);
        src/npc/sturgeon.o(.rodata);
        data/const/npc/sturgeon.o(.rodata);
        data/animations/npc/sturgeon.o(.rodata);
        src/npc/tingleSiblings.o(.rodata);
        data/animations/npc/tingleSiblings.o(.rodata);
        src/npc/stockwell.o(.rodata);
        data/animations/npc/stockwell.o(.rodata);
        src/npc/talon.o(.rodata);
        data/animations/npc/talon.o(.rodata);
        src/npc/malon.o(.rodata);
        data/animations/npc/malon.o(.rodata);
        src/npc/epona.o(.rodata);
        data/animations/npc/epona.o(.rodata);
        src/npc/milkCart.o(.rodata);
        data/animations/npc/milkCart.o(.rodata);
        src/npc/ghostBrothers.o(.rodata);
        data/animations/npc/ghostBrothers.o(.rodata);
        src/npc/smith.o(.rodata);
        data/animations/npc/smith.o(.rodata);
        src/npc/npc23.o(.rodata);
        src/npc/kingDaltus.o(.rodata);
        data/animations/npc/kingDaltus.o(.rodata);
        src/npc/ministerPotho.o(.rodata);
        data/animations/npc/ministerPotho.o(.rodata);
        src/npc/npc26.o(.rodata);
        data/animations/npc/npc26.o(.rodata);
        src/npc/vaati.o(.rodata);
        data/animations/npc/vaati.o(.rodata);
        src/npc/zelda.o(.rodata);
        src/npc/mutoh.o(.rodata);
        data/animations/npc/mutoh.o(.rodata);
        src/npc/carpenter.o(.rodata);
        data/animations/npc/carpenter.o(.rodata);
        src/npc/castorWildsStatue.o(.rodata);
        data/animations/npc/castorWildsStatue.o(.rodata);
        src/npc/cat.o(.rodata);
        data/animations/npc/cat.o(.rodata);
        src/npc/mountainMinish.o(.rodata);
        data/animations/npc/mountainMinish.o(.rodata);
        src/npc/melari.o(.rodata);
        data/animations/npc/melari.o(.rodata);
        src/npc/bladeBrothers.o(.rodata);
        data/animations/npc/bladeBrothers.o(.rodata);
        src/npc/cow.o(.rodata);
        data/animations/npc/cow.o(.rodata);
        src/npc/goron.o(.rodata);
        data/animations/npc/goron.o(.rodata);
        src/npc/goronMerchant.o(.rodata);
        data/animations/npc/goronMerchant.o(.rodata);
        src/npc/gorman.o(.rodata);
        data/animations/npc/gorman.o(.rodata);
        src/npc/dog.o(.rodata);
        data/animations/npc/dog.o(.rodata);
        src/npc/syrup.o(.rodata);
        data/animations/npc/syrup.o(.rodata);
        src/npc/rem.o(.rodata);
        data/animations/npc/rem.o(.rodata);
        src/npc/townMinish.o(.rodata);
        data/animations/npc/townMinish.o(.rodata);
        src/npc/librari.o(.rodata);
        data/animations/npc/librari.o(.rodata);
        src/npc/percy.o(.rodata);
        data/animations/npc/percy.o(.rodata);
        src/npc/vaatiReborn.o(.rodata);
        data/animations/npc/vaatiReborn.o(.rodata);
        data/animations/npc/moblinLady.o(.rodata);
        src/npc/librarians.o(.rodata);
        data/animations/npc/librarians.o(.rodata);
        src/npc/farmers.o(.rodata);
        data/animations/npc/farmers.o(.rodata);
        data/animations/npc/carlov.o(.rodata);
        src/npc/dampe.o(.rodata);
        data/animations/npc/dampe.o(.rodata);
        src/npc/drLeft.o(.rodata);
        data/animations/npc/drLeft.o(.rodata);
        data/animations/npc/kingGustaf.o(.rodata);
        data/animations/npc/gina.o(.rodata);
        data/animations/npc/simon.o(.rodata);
        data/animations/npc/anju.o(.rodata);
        src/npc/mama.o(.rodata);
        data/animations/npc/mama.o(.rodata);
        data/animations/npc/emma.o(.rodata);
        src/npc/teachers.o(.rodata);
        data/animations/npc/teachers.o(.rodata);
        src/npc/windTribespeople.o(.rodata);
        data/animations/npc/windTribespeople.o(.rodata);
        src/npc/gregal.o(.rodata);
        data/animations/npc/gregal.o(.rodata);
        src/npc/mayorHagen.o(.rodata);
        data/animations/npc/mayorHagen.o(.rodata);
        src/npc/bigGoron.o(.rodata);
        src/npc/ezlo.o(.rodata);
        src/npc/npc4E.o(.rodata);
        src/npc/npc4F.o(.rodata);
        data/animations/npc/npc4F.o(.rodata);
        src/npc/clothesRack.o(.rodata);
        data/animations/npc/clothesRack.o(.rodata);
        src/npc/picolyteBottle.o(.rodata);
        src/npc/smallTownMinish.o(.rodata);
        data/animations/npc/smallTownMinish.o(.rodata);
        src/npc/hurdyGurdyMan.o(.rodata);
        data/animations/npc/hurdyGurdyMan.o(.rodata);
        src/npc/cucco.o(.rodata);
        src/npc/cuccoChick.o(.rodata);
        src/npc/phonograph.o(.rodata);
        src/npc/npc58.o(.rodata);
        src/npcDefinitions.o(.rodata);
        src/npcUtils.o(.rodata);
        src/physics.o(.rodata);
        src/playerHitbox.o(.rodata);
        data/gfx/sprite_frames.o(.rodata);
        src/playerItem/playerItemPacciCaneProjectile.o(.rodata);
        src/playerItem/playerItemPacciCane.o(.rodata);
        src/player.o(.rodata);
        src/item.o(.rodata);
        src/item/itemSword.o(.rodata);
        src/item/itemLantern.o(.rodata);
        src/item/itemBoomerang.o(.rodata);
        src/item/itemBow.o(.rodata);
        src/item/itemBomb.o(.rodata);
        src/item/itemTryPickupObject.o(.rodata);
        src/item/itemPegasusBoots.o(.rodata);
        src/item/itemOcarina.o(.rodata);
        src/item/itemPacciCane.o(.rodata);
        src/item/itemShield.o(.rodata);
        src/item/itemGustJar.o(.rodata);
        src/item/itemMoleMitts.o(.rodata);
        src/item/itemJarEmpty.o(.rodata);
        data/item.o(.rodata);
        src/itemDefinitions.o(.rodata);
        src/playerUtils.o(.rodata);
        data/map/room_headers.o(.rodata);
        src/flags.o(.rodata);
        src/save.o(.rodata);
        src/script.o(.rodata);
        src/scroll.o(.rodata);
        src/object/itemOnGround.o(.rodata);
        src/object/deathFx.o(.rodata);
        data/animations/object/deathFx.o(.rodata);
        src/object/itemForSale.o(.rodata);
        src/object/button.o(.rodata);
        src/object/minishEmoticon.o(.rodata);
        data/animations/object/minishEmoticon.o(.rodata);
        src/object/pot.o(.rodata);
        data/animations/object/pot.o(.rodata);
        src/object/ezloCap.o(.rodata);
        data/animations/object/ezloCap.o(.rodata);
        src/object/blockPushed.o(.rodata);
        src/object/lockedDoor.o(.rodata);
        src/object/cameraTarget.o(.rodata);
        data/animations/object/cameraTarget.o(.rodata);
        src/object/linkHoldingItem.o(.rodata);
        src/object/chestSpawner.o(.rodata);
        data/animations/object/chestSpawner.o(.rodata);
        src/object/unusedSkull.o(.rodata);
        data/animations/object/unusedSkull.o(.rodata);
        src/object/specialFx.o(.rodata);
        data/animations/object/specialFx.o(.rodata);
        src/object/playerClone.o(.rodata);
        src/object/bush.o(.rodata);
        src/object/lightDoor.o(.rodata);
        src/object/railtrack.o(.rodata);
        data/animations/object/railtrack.o(.rodata);
        src/object/lilypadLarge.o(.rodata);
        src/object/chuchuBossParticle.o(.rodata);
        src/object/floatingPlatform.o(.rodata);
        src/object/gustJarParticle.o(.rodata);
        src/object/evilSpirit.o(.rodata);
        data/animations/object/evilSpirit.o(.rodata);
        src/object/houseDoorExterior.o(.rodata);
        src/object/rupee.o(.rodata);
        src/object/greatFairy.o(.rodata);
        data/animations/npc/greatFairy.o(.rodata);
        src/object/object1D.o(.rodata);
        src/object/moleMittsParticle.o(.rodata);
        data/animations/object/moleMittsParticle.o(.rodata);
        src/object/object1F.o(.rodata);
        src/object/smokeParticle.o(.rodata);
        src/object/dirtParticle.o(.rodata);
        src/object/figurineDevice.o(.rodata);
        data/animations/object/figurineDevice.o(.rodata);
        src/object/eyeSwitch.o(.rodata);
        data/animations/object/eyeSwitch.o(.rodata);
        src/object/pressurePlate.o(.rodata);
        src/object/bigBarrel.o(.rodata);
        data/animations/object/bigBarrel.o(.rodata);
        src/object/barrelInside.o(.rodata);
        src/object/pushableStatue.o(.rodata);
        data/animations/object/pushableStatue.o(.rodata);
        src/object/ambientClouds.o(.rodata);
        data/animations/object/ambientClouds.o(.rodata);
        src/object/flame.o(.rodata);
        data/animations/object/flame.o(.rodata);
        src/object/beanstalk.o(.rodata);
        data/animations/object/beanstalk.o(.rodata);
        src/object/smoke.o(.rodata);
        src/object/pushableRock.o(.rodata);
        data/animations/object/pushableRock.o(.rodata);
        src/object/hittableLever.o(.rodata);
        src/object/object30.o(.rodata);
        src/object/frozenFlower.o(.rodata);
        src/object/pullableMushroom.o(.rodata);
        data/animations/object/pullableMushroom.o(.rodata);
        src/object/bollard.o(.rodata);
        data/animations/object/bollard.o(.rodata);
        src/object/warpPoint.o(.rodata);
        data/animations/object/warpPoint.o(.rodata);
        src/object/carlovObject.o(.rodata);
        data/animations/object/carlovObject.o(.rodata);
        src/object/barrelSpiderweb.o(.rodata);
        src/object/object37.o(.rodata);
        src/object/jarPortal.o(.rodata);
        data/animations/object/jarPortal.o(.rodata);
        src/object/bossDoor.o(.rodata);
        data/animations/object/bossDoor.o(.rodata);
        src/object/whiteTriangleEffect.o(.rodata);
        src/object/macroMushroomStalk.o(.rodata);
        src/object/macroPlayer.o(.rodata);
        src/object/minishPortalCloseup.o(.rodata);
        src/object/minishVillageObject.o(.rodata);
        src/object/giantLeaf.o(.rodata);
        src/object/fairy.o(.rodata);
        src/object/linkFire.o(.rodata);
        src/object/swordParticle.o(.rodata);
        data/animations/object/swordParticle.o(.rodata);
        src/object/rotatingTrapdoor.o(.rodata);
        data/animations/object/rotatingTrapdoor.o(.rodata);
        src/object/lampParticle.o(.rodata);
        data/animations/object/lampParticle.o(.rodata);
        src/object/giantBookLadder.o(.rodata);
        src/object/heartContainer.o(.rodata);
        src/object/fileScreenObjects.o(.rodata);
        data/animations/object/fileScreenObjects.o(.rodata);
        src/object/chuchuBossStartParticle.o(.rodata);
        src/object/backgroundCloud.o(.rodata);
        src/object/chuchuBossCutscene.o(.rodata);
        src/object/pushableFurniture.o(.rodata);
        src/object/furniture.o(.rodata);
        src/object/minishSizedEntrance.o(.rodata);
        data/animations/object/minishSizedEntrance.o(.rodata);
        src/object/giantRock2.o(.rodata);
        src/object/object53.o(.rodata);
        src/object/pullableLever.o(.rodata);
        data/animations/object/pullableLever.o(.rodata);
        src/object/minecart.o(.rodata);
        data/animations/object/minecart.o(.rodata);
        src/object/thoughtBubble.o(.rodata);
        data/animations/object/thoughtBubble.o(.rodata);
        src/object/hiddenLadderDown.o(.rodata);
        src/object/gentariCurtain.o(.rodata);
        data/animations/object/gentariCurtain.o(.rodata);
        src/object/lavaPlatform.o(.rodata);
        data/animations/object/lavaPlatform.o(.rodata);
        src/object/paper.o(.rodata);
        src/object/bedCover.o(.rodata);
        src/object/mask.o(.rodata);
        src/object/houseDoorInterior.o(.rodata);
        src/object/whirlwind.o(.rodata);
        data/animations/object/whirlwind.o(.rodata);
        src/object/objectBlockingStairs.o(.rodata);
        src/object/swordsmanNewsletter.o(.rodata);
        src/object/ezloCapFlying.o(.rodata);
        src/object/giantTwig.o(.rodata);
        src/object/object63.o(.rodata);
        src/object/thunderbolt.o(.rodata);
        data/animations/object/thunderbolt.o(.rodata);
        src/object/ladderHoleInBookshelf.o(.rodata);
        src/object/gleerokParticle.o(.rodata);
        src/object/linkEmptyingBottle.o(.rodata);
        src/object/cutsceneMiscObject.o(.rodata);
        data/const/object/cutsceneMiscObject.o(.rodata);
        data/animations/object/cutsceneMiscObject.o(.rodata);
        src/object/crenelBeanSprout.o(.rodata);
        data/animations/object/crenelBeanSprout.o(.rodata);
        src/object/minecartDoor.o(.rodata);
        src/object/objectOnPillar.o(.rodata);
        src/object/mineralWaterSource.o(.rodata);
        src/object/object70.o(.rodata);
        src/object/pushableGrave.o(.rodata);
        src/object/stoneTablet.o(.rodata);
        src/object/lilypadSmall.o(.rodata);
        src/object/minishPortalStone.o(.rodata);
        src/object/bell.o(.rodata);
        data/animations/object/bell.o(.rodata);
        src/object/macroDecorations.o(.rodata);
        src/object/shrinkingHieroglyphs.o(.rodata);
        data/animations/object/shrinkingHieroglyphs.o(.rodata);
        src/object/steam.o(.rodata);
        src/object/pushableLever.o(.rodata);
        data/animations/object/pushableLever.o(.rodata);
        src/object/macroShoe.o(.rodata);
        src/object/objectOnSpinyBeetle.o(.rodata);
        src/object/picoBloom.o(.rodata);
        data/animations/object/picoBloom.o(.rodata);
        src/object/board.o(.rodata);
        src/object/bench.o(.rodata);
        src/object/bigVortex.o(.rodata);
        data/animations/object/bigVortex.o(.rodata);
        src/object/bigPushableLever.o(.rodata);
        data/animations/object/bigPushableLever.o(.rodata);
        src/object/smallIceBlock.o(.rodata);
        data/animations/object/smallIceBlock.o(.rodata);
        src/object/bigIceBlock.o(.rodata);
        data/animations/object/bigIceBlock.o(.rodata);
        src/object/trapdoor.o(.rodata);
        data/animations/object/trapdoor.o(.rodata);
        src/object/octorokBossObject.o(.rodata);
        src/object/macroBook.o(.rodata);
        data/animations/object/macroBook.o(.rodata);
        src/object/mazaalBossObject.o(.rodata);
        src/object/cabinFurniture.o(.rodata);
        src/object/doubleBookshelf.o(.rodata);
        src/object/book.o(.rodata);
        src/object/fireplace.o(.rodata);
        src/object/lightRay.o(.rodata);
        src/object/frozenWaterElement.o(.rodata);
        src/object/waterElement.o(.rodata);
        src/object/frozenOctorok.o(.rodata);
        src/object/bakerOven.o(.rodata);
        data/animations/object/bakerOven.o(.rodata);
        src/object/lamp.o(.rodata);
        data/animations/object/lamp.o(.rodata);
        src/object/bird.o(.rodata);
        data/animations/object/bird.o(.rodata);
        src/object/graveyardKey.o(.rodata);
        src/object/keyStealingTakkuri.o(.rodata);
        src/object/guruguruBar.o(.rodata);
        data/animations/object/guruguruBar.o(.rodata);
        src/object/macroAcorn.o(.rodata);
        src/object/vaati2Particle.o(.rodata);
        data/animations/object/vaati2Particle.o(.rodata);
        src/object/treeHidingPortal.o(.rodata);
        src/object/lightableSwitch.o(.rodata);
        src/object/fan.o(.rodata);
        data/animations/object/fan.o(.rodata);
        src/object/angryStatue.o(.rodata);
        data/animations/object/angryStatue.o(.rodata);
        src/object/palaceArchway.o(.rodata);
        src/object/objectA2.o(.rodata);
        data/animations/object/objectA2.o(.rodata);
        src/object/cloud.o(.rodata);
        src/object/minishLight.o(.rodata);
        src/object/sanctuaryStoneTablet.o(.rodata);
        data/animations/object/sanctuaryStoneTablet.o(.rodata);
        src/object/objectA8.o(.rodata);
        src/object/mulldozerSpawnPoint.o(.rodata);
        src/object/waterfallOpening.o(.rodata);
        src/object/vaati1Portal.o(.rodata);
        data/animations/object/vaati1Portal.o(.rodata);
        src/object/fourElements.o(.rodata);
        src/object/elementsBackground.o(.rodata);
        src/object/vaati3Arm.o(.rodata);
        data/animations/object/vaati3Arm.o(.rodata);
        src/object/metalDoor.o(.rodata);
        src/object/jailBars.o(.rodata);
        data/animations/object/jailBars.o(.rodata);
        data/animations/object/fanWind.o(.rodata);
        src/object/kinstoneSpark.o(.rodata);
        data/animations/object/kinstoneSpark.o(.rodata);
        src/object/japaneseSubtitle.o(.rodata);
        data/animations/object/japaneseSubtitle.o(.rodata);
        src/object/well.o(.rodata);
        src/object/windTribeTeleporter.o(.rodata);
        src/object/cuccoMinigame.o(.rodata);
        src/object/gyorgBossObject.o(.rodata);
        src/object/windcrest.o(.rodata);
        src/object/titleScreenObject.o(.rodata);
        src/object/pinwheel.o(.rodata);
        data/animations/object/pinwheel.o(.rodata);
        src/object/linkAnimation.o(.rodata);
        src/objectDefinitions.o(.rodata);
        src/playerItemDefinitions.o(.rodata);
        src/objectUtils.o(.rodata);
        data/animations/spriteAnimations166.o(.rodata);
        src/playerItem/playerItemShield.o(.rodata);
        src/playerItem/playerItemFireRodProjectile.o(.rodata);
#ifdef DEMO_USA
        src/demo.o(.rodata);
#endif
        src/staffroll.o(.rodata);
        data/const/staffroll.o(.rodata);
        src/data/areaMetadata.o(.rodata);
        src/menu/kinstoneMenu.o(.rodata);
        src/menu/figurineMenu.o(.rodata);
        data/gfx/figurines.o(.rodata);
        src/data/figurineMenuData.o(.rodata);
        src/menu/pauseMenu.o(.rodata);
        src/subtask/subtaskMapHint.o(.rodata);
        src/menu/pauseMenuScreen6.o(.rodata);
        src/subtask/subtaskLocalMapHint.o(.rodata);
        src/subtask/subtaskFastTravel.o(.rodata);
        data/const/subtask.o(.rodata);
        src/playerItem/playerItemSword.o(.rodata);
        data/projectile_functions.o(.rodata);
        src/projectile/darkNutSwordSlash.o(.rodata);
        src/projectile/rockProjectile.o(.rodata);
        data/animations/projectile/rockProjectile.o(.rodata);
        src/projectile/boneProjectile.o(.rodata);
        data/animations/projectile/boneProjectile.o(.rodata);
        src/projectile/moblinSpear.o(.rodata);
        src/projectile/dekuSeedProjectile.o(.rodata);
        src/projectile/projectile5.o(.rodata);
        src/projectile/dirtBallProjectile.o(.rodata);
        data/animations/projectile/dirtBallProjectile.o(.rodata);
        src/projectile/windProjectile.o(.rodata);
        data/animations/projectile/windProjectile.o(.rodata);
        src/projectile/fireProjectile.o(.rodata);
        data/animations/projectile/fireProjectile.o(.rodata);
        src/projectile/iceProjectile.o(.rodata);
        data/animations/projectile/iceProjectile.o(.rodata);
        src/projectile/gleerokProjectile.o(.rodata);
        src/projectile/keatonDagger.o(.rodata);
        src/projectile/guardLineOfSight.o(.rodata);
        src/projectile/arrowProjectile.o(.rodata);
        data/animations/projectile/arrowProjectile.o(.rodata);
        src/projectile/mazaalEnergyBeam.o(.rodata);
        data/animations/projectile/mazaalEnergyBeam.o(.rodata);
        src/projectile/octorokBossProjectile.o(.rodata);
        src/projectile/stalfosProjectile.o(.rodata);
        src/projectile/lakituCloudProjectile.o(.rodata);
        data/animations/projectile/lakituCloudProjectile.o(.rodata);
        src/projectile/lakituLightning.o(.rodata);
        data/animations/projectile/lakituLightning.o(.rodata);
        src/projectile/mandiblesProjectile.o(.rodata);
        data/animations/projectile/mandiblesProjectile.o(.rodata);
        src/projectile/removableDust.o(.rodata);
        src/projectile/spiderWeb.o(.rodata);
        data/animations/projectile/spiderWeb.o(.rodata);
        src/projectile/torchTrapProjectile.o(.rodata);
        data/animations/projectile/torchTrapProjectile.o(.rodata);
        src/projectile/v1DarkMagicProjectile.o(.rodata);
        data/animations/projectile/v1DarkMagicProjectile.o(.rodata);
        src/projectile/ballAndChain.o(.rodata);
        src/projectile/v1FireProjectile.o(.rodata);
        src/projectile/cannonballProjectile.o(.rodata);
        data/animations/projectile/cannonballProjectile.o(.rodata);
        src/projectile/v1EyeLaser.o(.rodata);
        data/animations/projectile/v1EyeLaser.o(.rodata);
        src/projectile/winder.o(.rodata);
        src/projectile/spikedRollers.o(.rodata);
        data/animations/projectile/spikedRollers.o(.rodata);
        src/projectile/v2Projectile.o(.rodata);
        data/animations/projectile/v2Projectile.o(.rodata);
        src/projectile/v3HandProjectile.o(.rodata);
        data/animations/projectile/v3HandProjectile.o(.rodata);
        src/projectile/v3ElectricProjectile.o(.rodata);
        src/projectile/gyorgTail.o(.rodata);
        src/projectile/gyorgMaleEnergyProjectile.o(.rodata);
        data/animations/projectile/gyorgMaleEnergyProjectile.o(.rodata);
        src/projectile/v3TennisBallProjectile.o(.rodata);
        src/playerItem/playerItemGust.o(.rodata);
        src/flagDebug.o(.rodata);
        src/playerItem/playerItemHeldObject.o(.rodata);
        src/title.o(.rodata);
        src/projectile.o(.rodata);
        src/playerItem/playerItemGustJar.o(.rodata);
        data/const/playerItem/playerItemGustJar.o(.rodata);
        data/gfx/fixed_type_gfx.o(.rodata);
        src/data/objPalettes.o(.rodata);
        src/movement.o(.rodata);
        src/data/transitions.o(.rodata);
        src/data/screenTransitions.o(.rodata);
        data/gfx/sprite_gfx.o(.rodata);
        data/gfx/frame_obj_lists.o(.rodata);
        data/map/map_data.o(.rodata);
        data/gfx/gfx_and_palettes.o(.rodata);
        data/strings.o(.rodata);
        data/gfx/extra_frame_offsets.o(.rodata);
        data/gfx/sprite_table.o(.rodata);
        src/gba/m4a.o(.rodata);
        data/sound/voicegroups.o(.rodata);
        data/sound/programmable_wave_samples.o(.rodata);
        src/sound.o(.rodata);
        data/sound/direct_sound_samples.o(.rodata);
        data/sound/sounds.o(.rodata);
        src/eeprom.o(.rodata);
    } >rom

    /* DWARF 2 sections */
    .debug_aranges  0 : { *(.debug_aranges) }
    .debug_pubnames 0 : { *(.debug_pubnames) }
    .debug_info     0 : { *(.debug_info) }
    .debug_abbrev   0 : { *(.debug_abbrev) }
    .debug_line     0 : { *(.debug_line) }
    .debug_frame    0 : { *(.debug_frame) }
    .debug_str      0 : { *(.debug_str) }
    .debug_loc      0 : { *(.debug_loc) }
    .debug_macinfo  0 : { *(.debug_macinfo) }

    /* Discard everything not specifically mentioned above. */
    /DISCARD/ :
    {
        *(*);
    }
}
